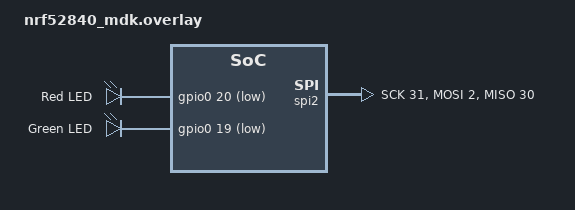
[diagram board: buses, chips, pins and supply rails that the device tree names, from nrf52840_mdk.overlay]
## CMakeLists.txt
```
cmake_minimum_required(VERSION 3.12.1)

include($ENV{ZEPHYR_BASE}/cmake/app/boilerplate.cmake NO_POLICY_SCOPE)
project(zepthyr_nrf_bridge)

set(CMAKE_EXPORT_COMPILE_COMMANDS y)

FILE(GLOB app_sources src/*.c )
FILE(GLOB dex_sources src/dexcom/*.c )
FILE(GLOB cc_sources src/cc2500/*.c )
FILE(GLOB gatt_sources src/gatt/*.c )
FILE(GLOB cgms_sources src/gatt/*/*.c )

target_sources(app PRIVATE 
    ${app_sources} 
    ${dex_sources} 
    ${cc_sources}
    ${gatt_sources}
    ${cgms_sources}
) 
```

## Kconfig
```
# Include Zephyr's Kconfig.
source "$ZEPHYR_BASE/Kconfig"

config CC2500
	bool "Use a CC2500"
	help
	   Use a CC2500 connected, otherwise it will be simulated

if CC2500
config CC2500_SPI
	string "Which SPI device to use"
	default "SPI_2"

config CC2500_GPIO
	string "Which GPIO device to use"
	default "GPIO_0"

config CC2500_GDO0_PIN
	int "GDO0 pin number"
	default 28

config CC2500_GDO2_PIN
	int "GDO2 pin number"
	default 27

config CC2500_CS_PIN
	int "nCS pin number"
	default 26
endif # CC2500

# Config for simulated data
if !CC2500

config CC2500_SIMULATED_TRANS_SPACING
	int "Time between transmissions in seconds"
	default 30

endif # !CC2500

config BATTERY_MEASUREMENT
	bool "Enable battery measurement"
	help
		Measure the battery using a voltage divider

if BATTERY_MEASUREMENT

config BATTERY_MEASUREMENT_GPIO
	string "Which GPIO device to use"
	default "GPIO_0"

config BATTERY_MEASUREMENT_EN_PIN
	int "battery measurement enable pin"
	default 25

config BATTERY_MEASUREMENT_ANALOG_PIN
	int "battery measurement analog pin"
	default 29

endif # BATTERY_MEASUREMENT
```

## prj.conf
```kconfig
CONFIG_OPENOCD_SUPPORT=y

CONFIG_BT=y
CONFIG_BT_DEBUG_LOG=y
CONFIG_BT_SMP=y
CONFIG_BT_SIGNING=y
CONFIG_BT_PERIPHERAL=y
CONFIG_BT_GATT_DIS=y
CONFIG_BT_ATT_PREPARE_COUNT=2
CONFIG_BT_PRIVACY=y
CONFIG_BT_DEVICE_NAME="hackaBLE"
CONFIG_BT_DEVICE_APPEARANCE=833
CONFIG_BT_DEVICE_NAME_DYNAMIC=y
CONFIG_BT_DEVICE_NAME_MAX=65
CONFIG_BT_MAX_PAIRED=10

CONFIG_BT_SETTINGS=y
CONFIG_FLASH=y
CONFIG_FLASH_PAGE_LAYOUT=y
CONFIG_FLASH_MAP=y
CONFIG_FCB=y
CONFIG_SETTINGS=y
CONFIG_SETTINGS_FCB=y

CONFIG_GPIO=y
CONFIG_GPIO_NRFX=y

CONFIG_LOG=y
CONFIG_LOG_PRINTK=n

CONFIG_SPI=y
CONFIG_SPI_NRFX=y
CONFIG_SPI_2=y
CONFIG_SPI_2_NRF_SPI=y

CONFIG_HEAP_MEM_POOL_SIZE=16384

CONFIG_SYS_POWER_MANAGEMENT=y
CONFIG_DEVICE_POWER_MANAGEMENT=y
```

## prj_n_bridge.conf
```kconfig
# Enable the CC2500 receiver
CONFIG_CC2500=y

# Enable battery voltage measurements
CONFIG_BATTERY_MEASUREMENT=n

# Enable BLE
CONFIG_BT=y
CONFIG_BT_DEBUG_LOG=y
CONFIG_BT_SMP=y
CONFIG_BT_PERIPHERAL=y
CONFIG_BT_GATT_DIS=y
CONFIG_BT_GATT_DIS_PNP=n
CONFIG_BT_DEVICE_NAME="Zephyr CGM Sensor"
CONFIG_BT_DEVICE_APPEARANCE=833

# Enable GPIO
CONFIG_GPIO=y
CONFIG_GPIO_NRFX=y

# Enable SPI
CONFIG_SPI=y
CONFIG_SPI_NRFX=y
CONFIG_SPI_2=y
CONFIG_SPI_2_NRF_SPI=y

# Enable heap memory
CONFIG_HEAP_MEM_POOL_SIZE=16384

# Enable power management
CONFIG_SYS_POWER_MANAGEMENT=y
CONFIG_DEVICE_POWER_MANAGEMENT=y
```

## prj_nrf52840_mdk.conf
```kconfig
# Enable the CC2500 receiver
CONFIG_CC2500=y

CONFIG_CC2500_SIMULATED_TRANS_SPACING=150

# Enable battery voltage measurements
CONFIG_BATTERY_MEASUREMENT=n

# ENable BLE
CONFIG_BT=y
CONFIG_BT_DEBUG_LOG=y
CONFIG_BT_SMP=y
CONFIG_BT_PERIPHERAL=y
CONFIG_BT_GATT_DIS=y
CONFIG_BT_GATT_DIS_PNP=n
CONFIG_BT_DEVICE_NAME="Zephyr CGM Sensor"
CONFIG_BT_DEVICE_APPEARANCE=833

CONFIG_BT_SETTINGS=y

# Enable flash
CONFIG_FLASH=y
CONFIG_FLASH_PAGE_LAYOUT=y
CONFIG_FLASH_MAP=y
CONFIG_FCB=y

# Enavle settings subsystem
CONFIG_SETTINGS=y
CONFIG_SETTINGS_FCB=y

# Enable GPIO
CONFIG_GPIO=y
CONFIG_GPIO_NRFX=y

# Enable logging
CONFIG_LOG=y

# Enable SPI
CONFIG_SPI=y
CONFIG_SPI_NRFX=y
CONFIG_SPI_2=y
CONFIG_SPI_2_NRF_SPI=y

# Enable heap memory
CONFIG_HEAP_MEM_POOL_SIZE=16384

# Enable power management
CONFIG_SYS_POWER_MANAGEMENT=y
CONFIG_DEVICE_POWER_MANAGEMENT=y
```

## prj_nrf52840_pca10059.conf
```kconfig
# Enable the CC2500 receiver
CONFIG_CC2500=y

# Enable battery voltage measurements
CONFIG_BATTERY_MEASUREMENT=n

# Enable BLE
CONFIG_BT=y
CONFIG_BT_DEBUG_LOG=y
CONFIG_BT_SMP=y
CONFIG_BT_PERIPHERAL=y
CONFIG_BT_GATT_DIS=y
CONFIG_BT_GATT_DIS_PNP=n
CONFIG_BT_DEVICE_NAME="Zephyr CGM Sensor"
CONFIG_BT_DEVICE_APPEARANCE=833

# Enable GPIO
CONFIG_GPIO=y
CONFIG_GPIO_NRFX=y

# Enable logging
CONFIG_LOG=y
CONFIG_LOG_PRINTK=n

# Enable heap memory
CONFIG_HEAP_MEM_POOL_SIZE=16384

CONFIG_SYS_POWER_MANAGEMENT=y
CONFIG_DEVICE_POWER_MANAGEMENT=y
```

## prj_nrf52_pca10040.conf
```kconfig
# Enable the CC2500 receiver
CONFIG_CC2500=y

# Enable battery voltage measurements
CONFIG_BATTERY_MEASUREMENT=n

# Enable BLE
CONFIG_BT=y
CONFIG_BT_DEBUG_LOG=y
CONFIG_BT_SMP=y
CONFIG_BT_PERIPHERAL=y
CONFIG_BT_GATT_DIS=y
CONFIG_BT_GATT_DIS_PNP=n
CONFIG_BT_DEVICE_NAME="Zephyr CGM Sensor"
CONFIG_BT_DEVICE_APPEARANCE=833

# Enable GPIO
CONFIG_GPIO=y
CONFIG_GPIO_NRFX=y

# Enable logging
CONFIG_LOG=y
CONFIG_LOG_PRINTK=n


# Enable SPI
CONFIG_SPI=y
CONFIG_SPI_NRFX=y
CONFIG_SPI_2=y
CONFIG_SPI_2_NRF_SPI=y

# Enable heap memory
CONFIG_HEAP_MEM_POOL_SIZE=16384

# Enable power management
CONFIG_SYS_POWER_MANAGEMENT=y
CONFIG_DEVICE_POWER_MANAGEMENT=y
```

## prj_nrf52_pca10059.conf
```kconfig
CONFIG_SIMULATE_RECEIVER=y

CONFIG_BT=y
CONFIG_BT_DEBUG_LOG=n
CONFIG_BT_SMP=y
CONFIG_BT_PERIPHERAL=y
CONFIG_BT_GATT_DIS=y
CONFIG_BT_GATT_DIS_PNP=n
CONFIG_BT_DEVICE_NAME="Zephyr CGM Sensor"
CONFIG_BT_DEVICE_APPEARANCE=833


CONFIG_LOG=n
CONFIG_LOG_PRINTK=n

CONFIG_HEAP_MEM_POOL_SIZE=16384

CONFIG_SYS_POWER_MANAGEMENT=y
CONFIG_DEVICE_POWER_MANAGEMENT=y
```

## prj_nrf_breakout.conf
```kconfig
# Enable the CC2500 receiver
CONFIG_CC2500=y

# Enable battery voltage measurements
CONFIG_BATTERY_MEASUREMENT=n

# Enable BLE
CONFIG_BT=y
CONFIG_BT_DEBUG_LOG=n
CONFIG_BT_SMP=y
CONFIG_BT_PERIPHERAL=y
CONFIG_BT_GATT_DIS=y
CONFIG_BT_GATT_DIS_PNP=n
CONFIG_BT_DEVICE_NAME="Zephyr CGM Sensor"
CONFIG_BT_DEVICE_APPEARANCE=833

# Enable console
CONFIG_CONSOLE=y
CONFIG_RTT_CONSOLE=y

# Enable heap memory
CONFIG_HEAP_MEM_POOL_SIZE=16384

# Enable power management
CONFIG_SYS_POWER_MANAGEMENT=y
CONFIG_DEVICE_POWER_MANAGEMENT=y
```

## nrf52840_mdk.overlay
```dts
/ {
	leds {
		compatible = "gpio-leds";
		led1: led_1 {
			gpios = <&gpio0 20 GPIO_INT_ACTIVE_LOW>;
			label = "Red LED";
		};
		led2: led_2 {
			gpios = <&gpio0 19 GPIO_INT_ACTIVE_LOW>;
			label = "Green LED";
		};
	};

	/* These aliases are provided for compatibility with samples */
	aliases {
		led0 = &led1;
		led1 = &led2;
	};
};

&spi2 {
	status = "ok";
	miso-pin = <30>;
	sck-pin = <31>;
	mosi-pin = <2>; /* Should have been 19, but not broken out  */
	spi-max-frequency = <500000>;
};
```

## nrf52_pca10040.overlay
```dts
&spi2 {
    status = "ok";
    sck-pin = <29>;
    mosi-pin = <25>;
    miso-pin = <28>;
    spi-max-frequency = <500000>;
};
```

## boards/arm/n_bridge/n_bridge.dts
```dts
/*
 * Copyright (c) 2019 Laird Connectivity
 *
 * SPDX-License-Identifier: Apache-2.0
 */

/dts-v1/;
#include <nordic/nrf52832_qfaa.dtsi>

/ {
	model = "n_bridge";
	compatible = "ssb,n_bridge", "nordic,nrf52832-qfaa",
		     "nordic,nrf52832";

	chosen {
		zephyr,sram = &sram0;
		zephyr,flash = &flash0;
		zephyr,code-partition = &slot0_partition;
	};

	leds {
		compatible = "gpio-leds";
		led1: led_1 {
			gpios = <&gpio0 20 GPIO_INT_ACTIVE_LOW>;
			label = "Red LED 0";
		};
		led2: led_2 {
			gpios = <&gpio0 19 GPIO_INT_ACTIVE_LOW>;
			label = "Green LED";
		};
	};

	/* These aliases are provided for compatibility with samples */
	aliases {
		led0 = &led1;
		led1 = &led2;
	};
};

&adc {
	status ="ok";
};

&gpiote {
	status ="ok";
};

&gpio0 {
	status ="ok";
};

&spi2 {
	status = "ok";
	miso-pin = <33>;
	sck-pin = <32>;
	mosi-pin = <31>;
	spi-max-frequency = <500000>;
    cs-gpios = <&gpio0 37 0>;
};

&flash0 {
	/*
	 * For more information, see:
	 * http://docs.zephyrproject.org/latest/guides/dts/index.html#flash-partitions
	 */
	partitions {
		compatible = "fixed-partitions";
		#address-cells = <1>;
		#size-cells = <1>;

		boot_partition: partition@0 {
			label = "mcuboot";
			reg = <0x00000000 0xc000>;
		};
		slot0_partition: partition@c000 {
			label = "image-0";
			reg = <0x0000C000 0x32000>;
		};
		slot1_partition: partition@3e000 {
			label = "image-1";
			reg = <0x0003E000 0x32000>;
		};
		scratch_partition: partition@70000 {
			label = "image-scratch";
			reg = <0x00070000 0xa000>;
		};
		storage_partition: partition@7a000 {
			label = "storage";
			reg = <0x0007a000 0x00006000>;
		};
	};
};
```

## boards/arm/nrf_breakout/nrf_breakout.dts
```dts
/*
 * Copyright (c) 2017 Shawn Nock <shawn@monadnock.ca>
 * Copyright (c) 2017 Linaro Limited
 *
 * SPDX-License-Identifier: Apache-2.0
 */

/dts-v1/;
#include <nordic/nrf52832_qfaa.dtsi>

/ {
	model = "Nordic nrf52 ali module";
	compatible = "nordic,nrf_breakout", "nordic,nrf52832-qfaa",
		     "nordic,nrf52832";

	chosen {
		zephyr,sram = &sram0;
		zephyr,flash = &flash0;
		zephyr,code-partition = &slot0_partition;
	};

	
};

&adc {
	status ="ok";
};

&gpiote {
	status ="ok";
};

&gpio0 {
	status ="ok";
};

&flash0 {
	/*
	 * For more information, see:
	 * http://docs.zephyrproject.org/latest/guides/dts/index.html#flash-partitions
	 */
	partitions {
		compatible = "fixed-partitions";
		#address-cells = <1>;
		#size-cells = <1>;

		boot_partition: partition@0 {
			label = "mcuboot";
			reg = <0x00000000 0xc000>;
		};
		slot0_partition: partition@c000 {
			label = "image-0";
			reg = <0x0000C000 0x32000>;
		};
		slot1_partition: partition@3e000 {
			label = "image-1";
			reg = <0x0003E000 0x32000>;
		};
		scratch_partition: partition@70000 {
			label = "image-scratch";
			reg = <0x00070000 0xa000>;
		};
		storage_partition: partition@7a000 {
			label = "storage";
			reg = <0x0007a000 0x00006000>;
		};
	};
};
```

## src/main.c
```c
#include <zephyr.h>
#include <misc/printk.h>
#include <zephyr/types.h>
#include <settings/settings.h>
#include <stddef.h>
#include <string.h>
#include <errno.h>
#include <misc/byteorder.h>

#include <bluetooth/bluetooth.h>
#include <bluetooth/hci.h>
#include <bluetooth/conn.h>
#include <bluetooth/uuid.h>
#include <bluetooth/gatt.h>
#include <bluetooth/controller.h>

#include <autoconf.h>

#include <device.h>
#include <gpio.h>

#include "dexcom/receiver.h"
#include "gatt/services/cgms.h"

/**********************************
 * 
 * 
 * BLE
 * 
 * 
 * *******************************/

struct bt_conn *default_conn;

static const struct bt_data ad[] = {
	BT_DATA_BYTES(BT_DATA_FLAGS, (BT_LE_AD_GENERAL | BT_LE_AD_NO_BREDR)),
	BT_DATA_BYTES(BT_DATA_UUID16_ALL, 0x0d, 0x18, 0x0f, 0x18, 0x05, 0x18),
};

static void connected(struct bt_conn *conn, u8_t err)
{
	if (err) {
		printk("Connection failed (err %u)\n", err);
	} else {
		default_conn = bt_conn_ref(conn);
		printk("Connected\n");
		cgms_send_all();
	}
}

static void disconnected(struct bt_conn *conn, u8_t reason)
{
	printk("Disconnected (reason %u)\n", reason);

	if (default_conn) {
		bt_conn_unref(default_conn);
		default_conn = NULL;
	}
}

static struct bt_conn_cb conn_callbacks = {
	.connected = connected,
	.disconnected = disconnected,
};

static void bt_ready(int err)
{
	if (err) {
		printk("Bluetooth init failed (err %d)\n", err);
		return;
	}

	printk("Bluetooth initialized\n");

	cgms_init();

	err = bt_le_adv_start(BT_LE_ADV_CONN_NAME, ad, ARRAY_SIZE(ad), NULL, 0);
	if (err) {
		printk("Advertising failed to start (err %d)\n", err);
		return;
	}

	printk("Advertising successfully started\n");
}

static void auth_cancel(struct bt_conn *conn)
{
	char addr[BT_ADDR_LE_STR_LEN];

	bt_addr_le_to_str(bt_conn_get_dst(conn), addr, sizeof(addr));

	printk("Pairing cancelled: %s\n", addr);
}

static struct bt_conn_auth_cb auth_cb_display = {
	.cancel = auth_cancel,
};

/*****************************************
 *
 * 
 * 
 * Dexcom receiver
 * 
 * 
 * 
 * **************************************/

void onDexcomPackageReceived(dexcom_package_t *pkt) {
	printk("Timestamp: %d\n", pkt->timestamp);
	printk("Raw: %d\n", pkt->rawIsig);
	printk("Fil: %d\n", pkt->filIsig);

	cgms_add_measurement(*pkt);
}

#ifdef CONFIG_CC2500
DEXCOM_RECEIVER(dexcom_receiver_ctx);
DEXCOM_RECEIVER_TIMER(dexcom_receiver_ctx);
DEXCOM_INTERRUPT_HANDLER(dexcom_receiver_ctx);

dexcom_package_t *pkt;
void init_dexcom() {
    dexcom_receiver_ctx.timeout_timer = &dexcom_receiver_ctx_timer;
    dexcom_receiver_ctx.gdo0_interrupt_handler = &dexcom_receiver_ctx_int_handler;
	dexcom_receiver_ctx.package_callback = onDexcomPackageReceived;
}

void run_cgm() {
	init_dexcom();
    start_cc2500(&dexcom_receiver_ctx);
}
#else
void init_dexcom() {}

void run_cgm() {
	dexcom_package_t simulated_package = {
		.timestamp = 0,
		.transmitterId = 0x01,
		.rawIsig = 72000,
		.filIsig =72000,
		.batLevel = 214
	};

    while(1) {
        k_sleep(K_SECONDS(CONFIG_CC2500_SIMULATED_TRANS_SPACING));

		simulated_package.timestamp = k_uptime_get_32();
		
		cgms_add_measurement(simulated_package);

    }
}
#endif

void main(void)
{
	u8_t addr[6] = {0x64, 0x40, 0x59, 0x22, 0xd2, 0xe7};
	bt_ctlr_set_public_addr(addr);

    int err;
	err = bt_enable(bt_ready);
	if (err) {
		printk("Bluetooth init failed (err %d)\n", err);
		return;
	}

	bt_conn_cb_register(&conn_callbacks);
    bt_conn_auth_cb_register(&auth_cb_display);

	run_cgm();

}
```

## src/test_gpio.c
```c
#include <zephyr.h>
#include <misc/printk.h>

//#include <autoconf.h>

#include <device.h>
#include <gpio.h>
#include <spi.h>

// Does this work for NRF52 -yes, but not general enough?
#define GPIO_OUT_DRV_NAME "GPIO_0"
#define GPIO_OUT_PIN  17

#define SPI_DRV_NAME "SPI_2"
#define SPI_CS_PIN 12

#define SEC_TO_TICK(sec) sec * 1200 // Trial and error, not accurate




void test_gpio(void)
{
    struct device *gpio_out_dev;
	int ret;
	int toggle = 1;

    // Get output driver
    gpio_out_dev = device_get_binding(GPIO_OUT_DRV_NAME);
	if (!gpio_out_dev) {
		printk("Cannot find %s!\n", GPIO_OUT_DRV_NAME);
		return;
	}

    // Configure output
    ret = gpio_pin_configure(gpio_out_dev, GPIO_OUT_PIN, (GPIO_DIR_OUT));
	if (ret) {
		printk("Error configuring pin %d!\n", GPIO_OUT_PIN);
        return;
	}

    // Enter infinite loop toggeling led
    while (1) {
		printk("Toggling pin %d\n", GPIO_OUT_PIN);

		ret = gpio_pin_write(gpio_out_dev, GPIO_OUT_PIN, toggle);
		if (ret) {
			printk("Error set pin %d!\n", GPIO_OUT_PIN);
		}

		if (toggle) {
			toggle = 0;
		} else {
			toggle = 1;
		}

		k_sleep(SEC_TO_TICK(2));
	}
}


void test_button_in(void) {
	struct device *gpio_out_dev;
	int ret;
	int toggle = 1;

    // Get output driver
    gpio_out_dev = device_get_binding(GPIO_OUT_DRV_NAME);
	if (!gpio_out_dev) {
		printk("Cannot find %s!\n", GPIO_OUT_DRV_NAME);
		return;
	}

    // Configure input
    ret = gpio_pin_configure(gpio_out_dev, 13, (GPIO_DIR_IN | GPIO_INT_ACTIVE_LOW | GPIO_PUD_PULL_UP));
	if (ret) {
		printk("Error configuring pin %d!\n", 13);
        return;
	}

	while (1) {
		ret = gpio_pin_read(gpio_out_dev, 13, &toggle);
		if (ret) {
			printk("Failed to read pin with id: %d\n", ret);
			return;
		}

		printk("Pin value is: %d \n", toggle);

		k_sleep(SEC_TO_TICK(2));
	}
}
```

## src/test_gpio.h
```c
#pragma once

void test_gpio(void);

void test_button_in(void);
```

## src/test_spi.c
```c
#include <zephyr.h>
#include <logging/log.h>
#include <logging/log_ctrl.h>

//#include <autoconf.h>

#include <device.h>
#include <gpio.h>
#include <spi.h>

#include "cc2500/cc2500_spi.h"
#include "cc2500/cc2500_reg.h"
#include "cc2500/cc2500.h"

#include "cc2500/utils.h"

// Does this work for NRF52 -yes, but not general enough?
#define GPIO_OUT_DRV_NAME "GPIO_0"
#define GPIO_OUT_PIN  17

#define SPI_DRV_NAME SPI_2_LABEL
#define SPI_CS_PIN 12
// #define SPI_2_LABEL					    DT_NORDIC_NRF_SPI_40023000_LABEL
// #define SPI_2_MISO_PIN					DT_NORDIC_NRF_SPI_40023000_MISO_PIN
// #define SPI_2_MOSI_PIN					DT_NORDIC_NRF_SPI_40023000_MOSI_PIN
// #define SPI_2_SCK_PIN					DT_NORDIC_NRF_SPI_40023000_SCK_PIN

#define SEC_TO_TICK(sec) sec * 1200 // Trial and error, not accurate

LOG_MODULE_REGISTER(test_cc2500);

u8_t data_buffer[64];

// This will have to be replaced by a macro
// Replace cc_ with a given prefix
static gpio_callback_t cc_gdo0_cb;
static gpio_callback_t cc_gdo2_cb;
cc2500_ctx_t cc_ctx = {
    .gdo0_cb = &cc_gdo0_cb,
    .gdo2_cb = &cc_gdo2_cb,
};

static struct k_work work;

volatile bool handeled_package = true;

void read_package_from_cc(struct k_work *item)
{
    handeled_package = true;
    LOG_INF("GDO0 asserted, which indicates end of packet received");

    // Config should have put the device into idle mode at end of package
    // but just to be sure
    cc2500_mode_idle(&cc_ctx);
    
    u8_t rxbytes, status;
    cc2500_read_status_reg(&cc_ctx, CC2500_REG_RXBYTES, &rxbytes, &status);

    LOG_INF("Status is: %02X, rxbytes is: %02X", status, rxbytes);

    // If overflow, ignore it all and retry
    if ((rxbytes & 0x80)) { 
        LOG_INF("Overflow in RX FIFO, ignore data");
        
    }
    else if ((rxbytes & 0x7F) > 0 && (status & 0x07) > 0) {
        LOG_INF("RXBYTES is: %02X", rxbytes);   
        u8_t num_bytes_rx = rxbytes & 0x7F; // Mask bit 7, which is overflow
        LOG_INF("%d bytes received", num_bytes_rx);
        
        cc2500_read_burst(&cc_ctx, CC2500_REG_RXFIFO, data_buffer, num_bytes_rx, NULL);

        printk("Data received: ");
        int i;
        for(i = 0; i < num_bytes_rx; i++) {
            printk("%02X ", data_buffer[i]);
        }


        uint16_t raw, filtered; 
        raw = data_buffer[12] << 8 | data_buffer[12];
        filtered = data_buffer[14] << 8 | data_buffer[15];
        float rawMmol = isigToMmol(convertFloat(reverse16(raw)));
        float filteredMmol = isigToMmol(convertFloat(reverse16(filtered)));


        printk("\n");
        printk("Raw: %f\n", rawMmol);
        printk("Fil: %f\n", filteredMmol);

    }    

    LOG_INF("Flushing RX FIFO");
    cc2500_flush_rxfifo(&cc_ctx);

    LOG_INF("Going back into RX mode");
    cc2500_mode_receive(&cc_ctx, 0);
    
    LOG_INF("Handler completed, listening...");
    return;
}


void submit_package_read(struct device *gpiob, struct gpio_callback *cb,
		    u32_t pins)
{
    if (!handeled_package) return;

    LOG_INF("Submitting read package job");
    k_work_init(&work, read_package_from_cc);
    k_work_submit(&work);
}


void test_cc2500(void) 
{
    LOG_INF("Testing CC2500");
    u8_t value, status;

    LOG_INF("Resetting CC2500");
    cc2500_send_strobe(&cc_ctx, CC2500_CMD_SRES, &status);

    LOG_INF("Asserting XTAL is stable");
    if(!cc2500_verify_osc_stabilization(&cc_ctx)) {
        LOG_INF("CC2500 didn't become ready in time");
        return;
    }
    
    LOG_INF("Reading off values to ensure CC2500 is working");
    cc2500_read_status_reg(&cc_ctx, CC2500_REG_PARTNUM, &value, &status);
    LOG_INF("Partnum: 0x%02X, should be 0x80", value);

    cc2500_read_status_reg(&cc_ctx, CC2500_REG_VERSION, &value, &status);
    LOG_INF("Version: 0x%02X, should be 0x03", value);

    // Write required register values
    LOG_INF("Writing Dexcom config to device");
    cc2500_write_register(&cc_ctx, CC2500_REG_PATABLE,      0x00, NULL);
    cc2500_write_register(&cc_ctx, CC2500_REG_IOCFG0,	    0x01, NULL);
    cc2500_write_register(&cc_ctx, CC2500_REG_PKTLEN,	    0xFF, NULL);
    cc2500_write_register(&cc_ctx, CC2500_REG_PKTCTRL1,	    0x04, NULL);
    cc2500_write_register(&cc_ctx, CC2500_REG_PKTCTRL0,	    0x05, NULL);
    cc2500_write_register(&cc_ctx, CC2500_REG_ADDR,	        0x00, NULL);
    cc2500_write_register(&cc_ctx, CC2500_REG_CHANNR,	    0x00, NULL);

    cc2500_write_register(&cc_ctx, CC2500_REG_FSCTRL1,	    0x0F, NULL);
    cc2500_write_register(&cc_ctx, CC2500_REG_FSCTRL0,	    0x00, NULL);
    
    cc2500_write_register(&cc_ctx, CC2500_REG_FREQ2,	    0x5D, NULL);
    cc2500_write_register(&cc_ctx, CC2500_REG_FREQ1,	    0x44, NULL);
    cc2500_write_register(&cc_ctx, CC2500_REG_FREQ0,	    0xEB, NULL);
    
    cc2500_write_register(&cc_ctx, CC2500_REG_FREND1,	    0xB6, NULL);
    cc2500_write_register(&cc_ctx, CC2500_REG_FREND0,	    0x10, NULL);
    
    cc2500_write_register(&cc_ctx, CC2500_REG_MDMCFG4,	    0x7A, NULL);
    cc2500_write_register(&cc_ctx, CC2500_REG_MDMCFG3,	    0xF8, NULL);
    cc2500_write_register(&cc_ctx, CC2500_REG_MDMCFG2,	    0x73, NULL);
    cc2500_write_register(&cc_ctx, CC2500_REG_MDMCFG1,	    0x23, NULL);
    cc2500_write_register(&cc_ctx, CC2500_REG_MDMCFG0,	    0x3B, NULL);
    
    cc2500_write_register(&cc_ctx, CC2500_REG_DEVIATN,	    0x40, NULL);
    
    cc2500_write_register(&cc_ctx, CC2500_REG_MCSM2,	    0x07, NULL);
    cc2500_write_register(&cc_ctx, CC2500_REG_MCSM1, 	    0x30, NULL);
    cc2500_write_register(&cc_ctx, CC2500_REG_MCSM0,	    0x18, NULL);
    
    cc2500_write_register(&cc_ctx, CC2500_REG_FOCCFG,	    0x16, NULL);
    
    cc2500_write_register(&cc_ctx, CC2500_REG_FSCAL3,	    0xA9, NULL);
    cc2500_write_register(&cc_ctx, CC2500_REG_FSCAL2,	    0x0A, NULL);
    cc2500_write_register(&cc_ctx, CC2500_REG_FSCAL1,	    0x00, NULL);
    cc2500_write_register(&cc_ctx, CC2500_REG_FSCAL0,	    0x11, NULL);
    
    cc2500_write_register(&cc_ctx, CC2500_REG_AGCCTRL2,	    0x03, NULL);
    cc2500_write_register(&cc_ctx, CC2500_REG_AGCCTRL1,	    0x00, NULL);
    cc2500_write_register(&cc_ctx, CC2500_REG_AGCCTRL0,	    0x91, NULL);
    
    cc2500_write_register(&cc_ctx, CC2500_REG_TEST2,	    0x81, NULL);
    cc2500_write_register(&cc_ctx, CC2500_REG_TEST1,	    0x35, NULL);
    cc2500_write_register(&cc_ctx, CC2500_REG_TEST0,	    0x0B, NULL);
    
    cc2500_write_register(&cc_ctx, CC2500_REG_FOCCFG,	    0x0A, NULL);
    
    cc2500_write_register(&cc_ctx, CC2500_REG_BSCFG,	    0x6C, NULL);

    LOG_INF("Registering callback for GDO0");
    cc2500_register_gdo0_handler(&cc_ctx, submit_package_read, GPIO_INT_EDGE | GPIO_INT_ACTIVE_HIGH);

    LOG_INF("Going into RX mode");
    cc2500_mode_receive(&cc_ctx, 0);

    LOG_INF("All setup completed, listening...");
}
```
